# STM32F778 register map
File version: 1.7
CPU: CM7 r0p1, little endian, MPU, FPU, 4 interrupt priority bits
Registers are 32-bit, read-write, reset 0x0 unless marked. A register's access mark holds for its fields unless they carry their own. Offsets are from the block's base; [hi:lo] are bit positions; lines under a group give offsets from that group; {n}, {i} and the like mark numbered series.

## DFSDM — Digital filter for sigma delta modulators
Base 0x40017400
{0x0+0x20*i} CH{i} (i=0..7) group — DFSDM channel configuration cluster
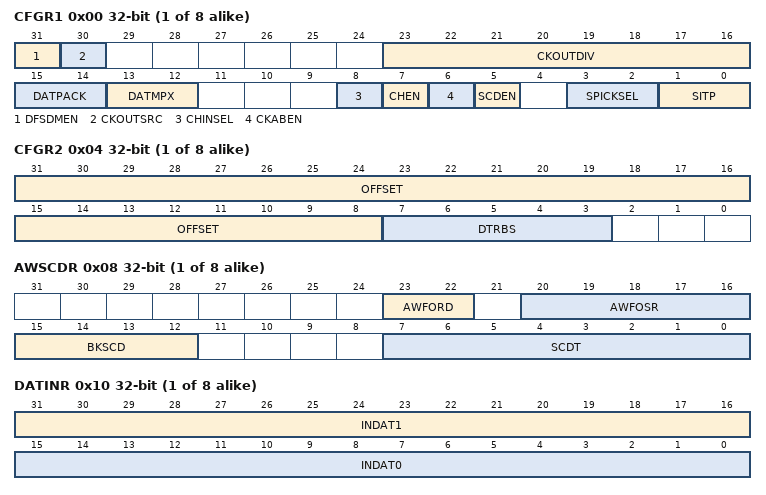
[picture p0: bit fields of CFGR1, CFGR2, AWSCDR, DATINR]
  0x00 CFGR1 — DFSDM channel configuration 0 register 1
    [31] DFSDMEN — Global enable for DFSDM interface
      0=Disabled (DFSDM interface disabled); 1=Enabled (DFSDM interface enabled)
    [30] CKOUTSRC — Output serial clock source selection
      0=SYSCLK (Source for output clock is from system clock); 1=AUDCLK (Source for output clock is from audio clock)
    [23:16] CKOUTDIV — Output serial clock divider
    [15:14] DATPACK — Data packing mode in DFSDM_CHDATINyR register
      0=Standard: input data in DFSDM_CHyDATINR register are stored only in INDAT0[15:0]. To empty DFSDM_CHyDATINR register one sample must be read by the DFSDM filter from channel y; 1=: Interleaved: input data in DFSDM_CHyDATINR register are stored as two samples: –first sample in INDAT0[15:0] (assigned to channel y) –second sample INDAT1[15:0] (assigned to channel y); 2=Dual: input data in DFSDM_CHyDATINR register are stored as two samples: –first sample INDAT0[15:0] (assigned to channel y) –second sample INDAT1[15:0] (assigned to channel y+1)
    [13:12] DATMPX — Input data multiplexer for channel 0
      0=External (Data to channel y are taken from external serial inputs as 1-bit values. DFSDM_CHyDATINR register is write protected); 1=ADC (Data to channel y are taken from internal analog to digital converter ADCy+1 output register update as 16-bit values (if ADCy+1 is available). Data from ADCs are written into INDAT0[15:0] part of DFSDM_CHyDATINR register); 2=Internal (Data to channel y are taken from internal DFSDM_CHyDATINR register by direct CPU/DMA write. There can be written one or two 16-bit data samples according DATPACK[1:0] bit field setting)
    [8] CHINSEL — Channel inputs selection
      0=SameChannel (Channel inputs are taken from pins of the same channel y); 1=FollowingChannel (Channel inputs are taken from pins of the following channel (channel (y+1) modulo 8))
    [7] CHEN — Channel 0 enable
      0=Disabled (Channel y disabled); 1=Enabled (Channel y enabled)
    [6] CKABEN — Clock absence detector enable on channel 0
      0=Disabled (Clock absence detector disabled on channel y); 1=Enabled (Clock absence detector enabled on channel y)
    [5] SCDEN — Short-circuit detector enable on channel 0
      0=Disabled (Input channel y will not be guarded by the short-circuit detector); 1=Enabled (Input channel y will be continuously guarded by the short-circuit detector)
    [3:2] SPICKSEL — SPI clock select for channel 0
      0=CKIN (Clock coming from external CKINy input - sampling point according SITP[1:0]); 1=CKOUT (Clock coming from internal CKOUT output - sampling point according SITP[1:0]); 2=CKOUTSecondFalling (Clock coming from internal CKOUT - sampling point on each second CKOUT falling edge. For connection to external Σ∆ modulator which divides its clock input (from CKOUT) by 2 to generate its output serial communication clock (and this output clock change is active on each clock input rising edge)); 3=CKOUTSecondRising (Clock coming from internal CKOUT output - sampling point on each second CKOUT rising edge. For connection to external Σ∆ modulator which divides its clock input (from CKOUT) by 2 to generate its output serial communication clock (and this output clock change is active on each clock input falling edge))
    [1:0] SITP — Serial interface type for channel 0
      0=SPIRisingEdge (SPI with rising edge to strobe data); 1=SPIFallingEdge (SPI with falling edge to strobe data); 2=Manchester coded input on DATINy pin: rising edge = logic 0, falling edge = logic 1; 3=ManchesterInverted (Manchester coded input on DATINy pin: rising edge = logic 1, falling edge = logic 0)
  0x04 CFGR2 — DFSDM channel configuration 0 register 2
    [31:8] OFFSET — 24-bit calibration offset for channel 0
    [7:3] DTRBS — Data right bit-shift for channel 0
  0x08 AWSCDR — DFSDM analog watchdog and short-circuit detector register
    [23:22] AWFORD — Analog watchdog Sinc filter order on channel 0
      0=FastSinc filter type; 1=Sinc1 filter type; 2=Sinc2 filter type; 3=Sinc3 filter type
    [20:16] AWFOSR — Analog watchdog filter oversampling ratio (decimation rate) on channel 0
    [15:12] BKSCD — Break signal assignment for short-circuit detector on channel 0
    [7:0] SCDT — short-circuit detector threshold for channel 0
  0x0C WDATR ro — DFSDM channel watchdog filter data register
    [15:0] WDATA — Input channel y watchdog data
  0x10 DATINR — DFSDM channel data input register
    [31:16] INDAT1 — Input data for channel 1
    [15:0] INDAT0 — Input data for channel 0
{0x100+0x80*i} FLT{i} (i=0..3) group — DFSDM cluster: CR1, CR2, ISR, ICR, JCHGR, FCR, JDATAR, RDATAR, AWHTR, AWLTR, AWSR, AWCFR, EXMAX, EXMIN, CNVTIMR registers
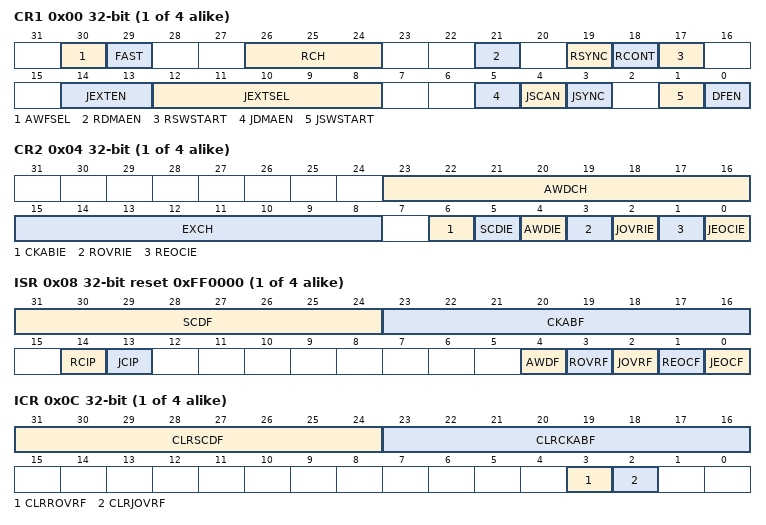
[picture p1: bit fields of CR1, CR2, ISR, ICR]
  0x00 CR1 — DFSDM control register 1
    [30] AWFSEL — Analog watchdog fast mode select
      0=Output (Analog watchdog on data output value (after the digital filter). The comparison is done after offset correction and shift); 1=Transceiver (Analog watchdog on channel transceivers value (after watchdog filter))
    [29] FAST — Fast conversion mode selection for regular conversions
      0=Disabled (Fast conversion mode disabled); 1=Enabled (Fast conversion mode enabled)
    [26:24] RCH — Regular channel selection
      {v}=Channel {v} is selected as regular channel (v=0..7)
    [21] RDMAEN — DMA channel enabled to read data for the regular conversion
      0=Disabled (The DMA channel is not enabled to read regular data); 1=Enabled (The DMA channel is enabled to read regular data)
    [19] RSYNC — Launch regular conversion synchronously with DFSDM0
      0=NoLaunch (Do not launch a regular conversion synchronously with DFSDM_FLT0); 1=Launch a regular conversion in this DFSDM_FLTx at the very moment when a regular conversion is launched in DFSDM_FLT0
    [18] RCONT — Continuous mode selection for regular conversions
      0=Once (The regular channel is converted just once for each conversion request); 1=Continuous (The regular channel is converted repeatedly after each conversion request)
    [17] RSWSTART — Software start of a conversion on the regular channel
      on write: 1=Start (Writing ‘1’ makes a request to start a conversion on the regular channel and causes RCIP to become ‘1’. If RCIP=1 already, writing to RSWSTART has no effect. Writing ‘1’ has no effect if RSYNC=1)
    [14:13] JEXTEN — Trigger enable and trigger edge selection for injected conversions
      0=Disabled (Trigger detection is disabled); 1=RisingEdge (Each rising edge on the selected trigger makes a request to launch an injected conversion); 2=FallingEdge (Each falling edge on the selected trigger makes a request to launch an injected conversion); 3=BothEdges (Both rising edges and falling edges on the selected trigger make requests to launch injected conversions)
    [12:8] JEXTSEL — Trigger signal selection for launching injected conversions
    [5] JDMAEN — DMA channel enabled to read data for the injected channel group
      0=Disabled (The DMA channel is not enabled to read injected data); 1=Enabled (The DMA channel is enabled to read injected data)
    [4] JSCAN — Scanning conversion mode for injected conversions
      0=Single (One channel conversion is performed from the injected channel group and next the selected channel from this group is selected); 1=Series (The series of conversions for the injected group channels is executed, starting over with the lowest selected channel)
    [3] JSYNC — Launch an injected conversion synchronously with the DFSDM0 JSWSTART trigger
      0=Disabled (Do not launch an injected conversion synchronously with DFSDM_FLT0); 1=Enabled (Launch an injected conversion in this DFSDM_FLTx at the very moment when an injected conversion is launched in DFSDM_FLT0 by its JSWSTART trigger)
    [1] JSWSTART — Start a conversion of the injected group of channels
      on write: 1=Start (Writing ‘1’ makes a request to convert the channels in the injected conversion group, causing JCIP to become ‘1’ at the same time. If JCIP=1 already, then writing to JSWSTART has no effect. Writing ‘1’ has no effect if JSYNC=1)
    [0] DFEN — DFSDM enable
      0=Disabled (DFSDM_FLTx is disabled. All conversions of given DFSDM_FLTx are stopped immediately and all DFSDM_FLTx functions are stopped); 1=Enabled (DFSDM_FLTx is enabled. If DFSDM_FLTx is enabled, then DFSDM_FLTx starts operating according to its setting)
  0x04 CR2 — DFSDM control register 2
    [23:16] AWDCH — Analog watchdog channel selection
      0=Disabled (Analog watchdog is disabled on channel y); 1=Enabled (Analog watchdog is enabled on channel y)
    [15:8] EXCH — Extremes detector channel selection
      0=Disabled (Extremes detector does not accept data from channel y); 1=Enabled (Extremes detector accepts data from channel y)
    [6] CKABIE — Clock absence interrupt enable
      0=Disabled (Detection of channel input clock absence interrupt is disabled); 1=Enabled (Detection of channel input clock absence interrupt is enabled)
    [5] SCDIE — Short-circuit detector interrupt enable
      0=Disabled (Short-circuit detector interrupt is disabled); 1=Enabled (Short-circuit detector interrupt is enabled)
    [4] AWDIE — Analog watchdog interrupt enable
      0=Disabled (Analog watchdog interrupt is disabled); 1=Enabled (Analog watchdog interrupt is enabled)
    [3] ROVRIE — Regular data overrun interrupt enable
      0=Disabled (Regular data overrun interrupt is disabled); 1=Enabled (Regular data overrun interrupt is enabled)
    [2] JOVRIE — Injected data overrun interrupt enable
      0=Disabled (Injected data overrun interrupt is disabled); 1=Enabled (Injected data overrun interrupt is enabled)
    [1] REOCIE — Regular end of conversion interrupt enable
      0=Disabled (Regular end of conversion interrupt is disabled); 1=Enabled (Regular end of conversion interrupt is enabled)
    [0] JEOCIE — Injected end of conversion interrupt enable
      0=Disabled (Injected end of conversion interrupt is disabled); 1=Enabled (Injected end of conversion interrupt is enabled)
  0x08 ISR ro reset 0xFF0000 — DFSDM interrupt and status register
    [31:24] SCDF — short-circuit detector flag
      0=Clear (No short-circuit detector event occurred on channel y); 1=Set (The short-circuit detector counter reaches, on channel y, the value programmed in the DFSDM_CHyAWSCDR registers)
    [23:16] CKABF — Clock absence flag
      0=Clear (Clock signal on channel y is present.); 1=Set (Clock signal on channel y is not present)
    [14] RCIP — Regular conversion in progress status
      0=NotInProgress (No request to convert the regular channel has been issued); 1=InProgress (The conversion of the regular channel is in progress or a request for a regular conversion is pending)
    [13] JCIP — Injected conversion in progress status
      0=NotInProgress (No request to convert the injected channel group (neither by software nor by trigger) has been issued); 1=InProgress (The conversion of the injected channel group is in progress or a request for a injected conversion is pending, due either to ‘1’ being written to JSWSTART or to a trigger detection)
    [4] AWDF — Analog watchdog
      0=Clear (No Analog watchdog event occurred); 1=Set (The analog watchdog block detected voltage which crosses the value programmed in the DFSDM_FLTxAWLTR or DFSDM_FLTxAWHTR registers)
    [3] ROVRF — Regular conversion overrun flag
      0=Clear (No regular conversion overrun has occurred); 1=Set (A regular conversion overrun has occurred, which means that a regular conversion finished while REOCF was already ‘1’. RDATAR is not affected by overruns)
    [2] JOVRF — Injected conversion overrun flag
      0=Clear (No injected conversion overrun has occurred); 1=Set (An injected conversion overrun has occurred, which means that an injected conversion finished while JEOCF was already ‘1’. JDATAR is not affected by overruns)
    [1] REOCF — End of regular conversion flag
      0=Clear (No regular conversion has completed); 1=Set (A regular conversion has completed and its data may be read)
    [0] JEOCF — End of injected conversion flag
      0=Clear (No injected conversion has completed); 1=Set (An injected conversion has completed and its data may be read)
  0x0C ICR — DFSDM interrupt flag clear register
    [31:24] CLRSCDF — Clear the short-circuit detector flag
    [23:16] CLRCKABF — Clear the clock absence flag
    [3] CLRROVRF — Clear the regular conversion overrun flag
      on write: 1=Clear (Writing ‘1’ clears the ROVRF bit in the DFSDM_FLTxISR register)
    [2] CLRJOVRF — Clear the injected conversion overrun flag
      on write: 1=Clear (Writing ‘1’ clears the JOVRF bit in the DFSDM_FLTxISR register)
  0x10 JCHGR reset 0x1 — DFSDM injected channel group selection register
    [7:0] JCHG — Injected channel group selection
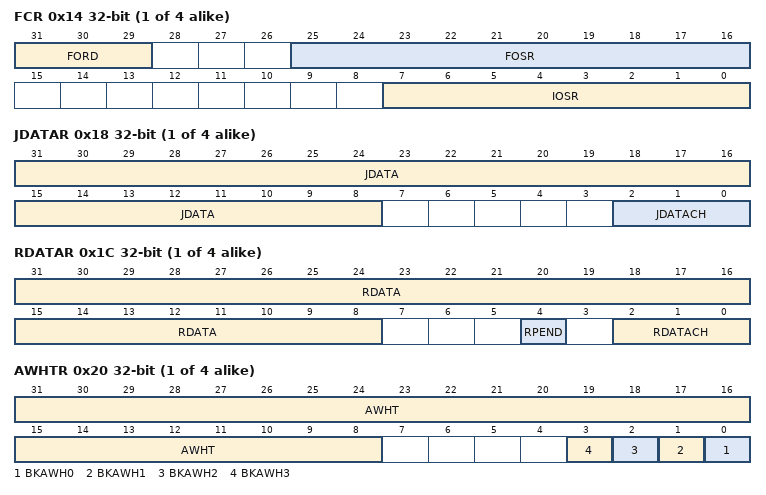
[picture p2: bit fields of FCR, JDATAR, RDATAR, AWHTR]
  0x14 FCR — DFSDM filter control register
    [31:29] FORD — Sinc filter order
      0=FastSinc filter type; {v}=Sinc{v} filter type (v=1..5)
    [25:16] FOSR — Sinc filter oversampling ratio (decimation rate)
    [7:0] IOSR — Integrator oversampling ratio (averaging length)
  0x18 JDATAR ro — DFSDM data register for injected group
    [31:8] JDATA — Injected group conversion data
    [2:0] JDATACH — Injected channel most recently converted
  0x1C RDATAR ro — DFSDM data register for the regular channel
    [31:8] RDATA — Regular channel conversion data
    [4] RPEND — Regular channel pending data
    [2:0] RDATACH — Regular channel most recently converted
  0x20 AWHTR — DFSDM analog watchdog high threshold register
    [31:8] AWHT — Analog watchdog high threshold
    [n] BKAWH{n} (n=0..3) — Break signal assignment to analog watchdog high threshold event
      0=NotAssigned (Break i signal is not assigned to an analog watchdog high threshold event); 1=Assigned (Break i signal is assigned to an analog watchdog high threshold event)
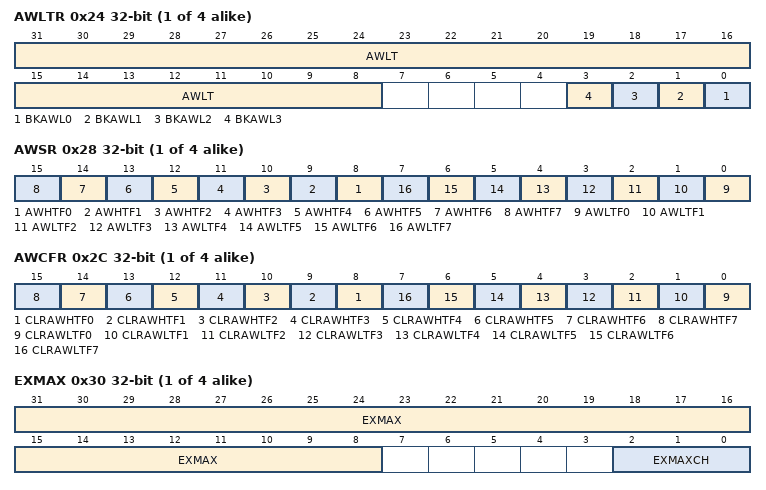
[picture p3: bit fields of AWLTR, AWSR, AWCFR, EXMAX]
  0x24 AWLTR — DFSDM analog watchdog low threshold register
    [31:8] AWLT — Analog watchdog low threshold
    [n] BKAWL{n} (n=0..3) — Break signal assignment to analog watchdog low threshold event
      0=NotAssigned (Break i signal is not assigned to an analog watchdog low threshold event); 1=Assigned (Break i signal is assigned to an analog watchdog low threshold event)
  0x28 AWSR ro — DFSDM analog watchdog status register
    [n+8] AWHTF{n} (n=0..7) — Analog watchdog high threshold flag
      0=NoError (No high threshold error); 1=Error (A high threshold error on channel y)
    [n] AWLTF{n} (n=0..7) — Analog watchdog low threshold flag
      0=NoError (No low threshold error); 1=Error (A low threshold error on channel y)
  0x2C AWCFR — DFSDM analog watchdog clear flag register
    [n+8] CLRAWHTF{n} (n=0..7) write-1-clears — Clear the analog watchdog high threshold flag
      on write: 1=Clear the corresponding AWHTF[y] bit
    [n] CLRAWLTF{n} (n=0..7) write-1-clears — Clear the analog watchdog low threshold flag
      on write: 1=Clear the corresponding AWLTF[y] bit
  0x30 EXMAX ro — DFSDM Extremes detector maximum register
    [31:8] EXMAX — Extremes detector maximum value
    [2:0] EXMAXCH — Extremes detector maximum data channel
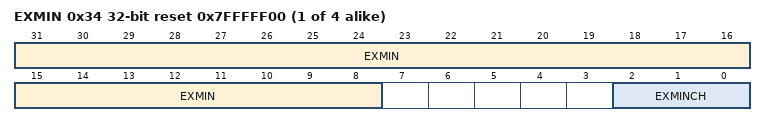
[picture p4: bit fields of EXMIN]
  0x34 EXMIN ro reset 0x7FFFFF00 — DFSDM Extremes detector minimum register
    [31:8] EXMIN — Extremes detector minimum value
    [2:0] EXMINCH — Extremes detector minimum data channel
  0x38 CNVTIMR ro — DFSDM conversion timer register
    [31:4] CNVCNT — 28-bit timer counting conversion time
